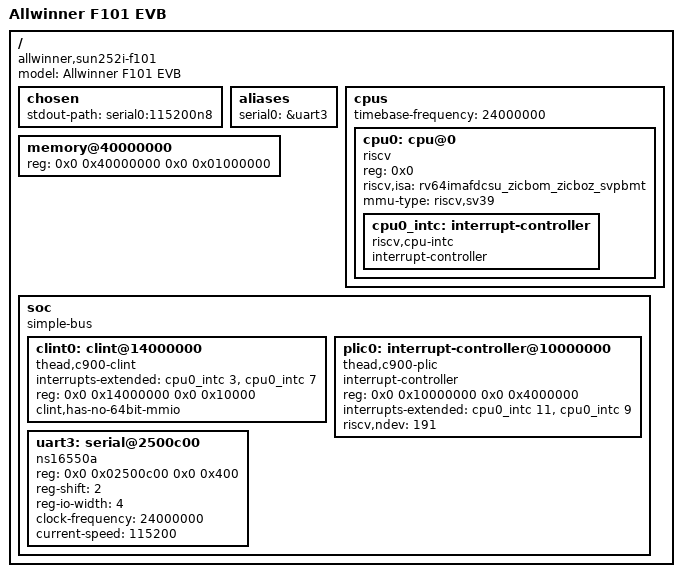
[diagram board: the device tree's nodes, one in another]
// SPDX-License-Identifier: GPL-2.0+ OR MIT
/*
 * Device tree for OpenSBI and the EDK2 payload on the F101 EVB, C907 reset into RV64.
 * The 16 MiB of PSRAM at 0x40000000: the EDK2 image is at the start, this blob and OpenSBI
 * (reserved by OpenSBI itself) at the end. The console is UART3 (PE08/PE09), set up by the loader.
 */

/dts-v1/;

/ {
	model = "Allwinner F101 EVB";
	compatible = "allwinner,sun252i-f101", "allwinner,sun252iw2p1";
	#address-cells = <2>;
	#size-cells = <2>;

	chosen {
		stdout-path = "serial0:115200n8";
	};

	aliases {
		serial0 = &uart3;
	};

	cpus {
		#address-cells = <1>;
		#size-cells = <0>;
		timebase-frequency = <24000000>;

		cpu0: cpu@0 {
			device_type = "cpu";
			reg = <0x0>;
			status = "okay";
			compatible = "riscv";
			riscv,isa = "rv64imafdcsu_zicbom_zicboz_svpbmt";
			mmu-type = "riscv,sv39";
			cpu0_intc: interrupt-controller {
				#address-cells = <0>;
				#interrupt-cells = <1>;
				compatible = "riscv,cpu-intc";
				interrupt-controller;
			};
		};
	};

	memory@40000000 {
		device_type = "memory";
		reg = <0x0 0x40000000 0x0 0x01000000>;
	};

	soc {
		#address-cells = <2>;
		#size-cells = <2>;
		compatible = "simple-bus";
		ranges;

		clint0: clint@14000000 {
			compatible = "thead,c900-clint";
			interrupts-extended = <&cpu0_intc 3 &cpu0_intc 7>;
			reg = <0x0 0x14000000 0x0 0x10000>;
			clint,has-no-64bit-mmio;
		};

		plic0: interrupt-controller@10000000 {
			compatible = "thead,c900-plic";
			#address-cells = <2>;
			#interrupt-cells = <2>;
			interrupt-controller;
			reg = <0x0 0x10000000 0x0 0x4000000>;
			interrupts-extended = <&cpu0_intc 11 &cpu0_intc 9>;
			riscv,ndev = <191>;
		};

		uart3: serial@2500c00 {
			compatible = "ns16550a", "snps,dw-apb-uart";
			reg = <0x0 0x02500c00 0x0 0x400>;
			reg-shift = <2>;
			reg-io-width = <4>;
			clock-frequency = <24000000>;
			current-speed = <115200>;
			status = "okay";
		};
	};
};
